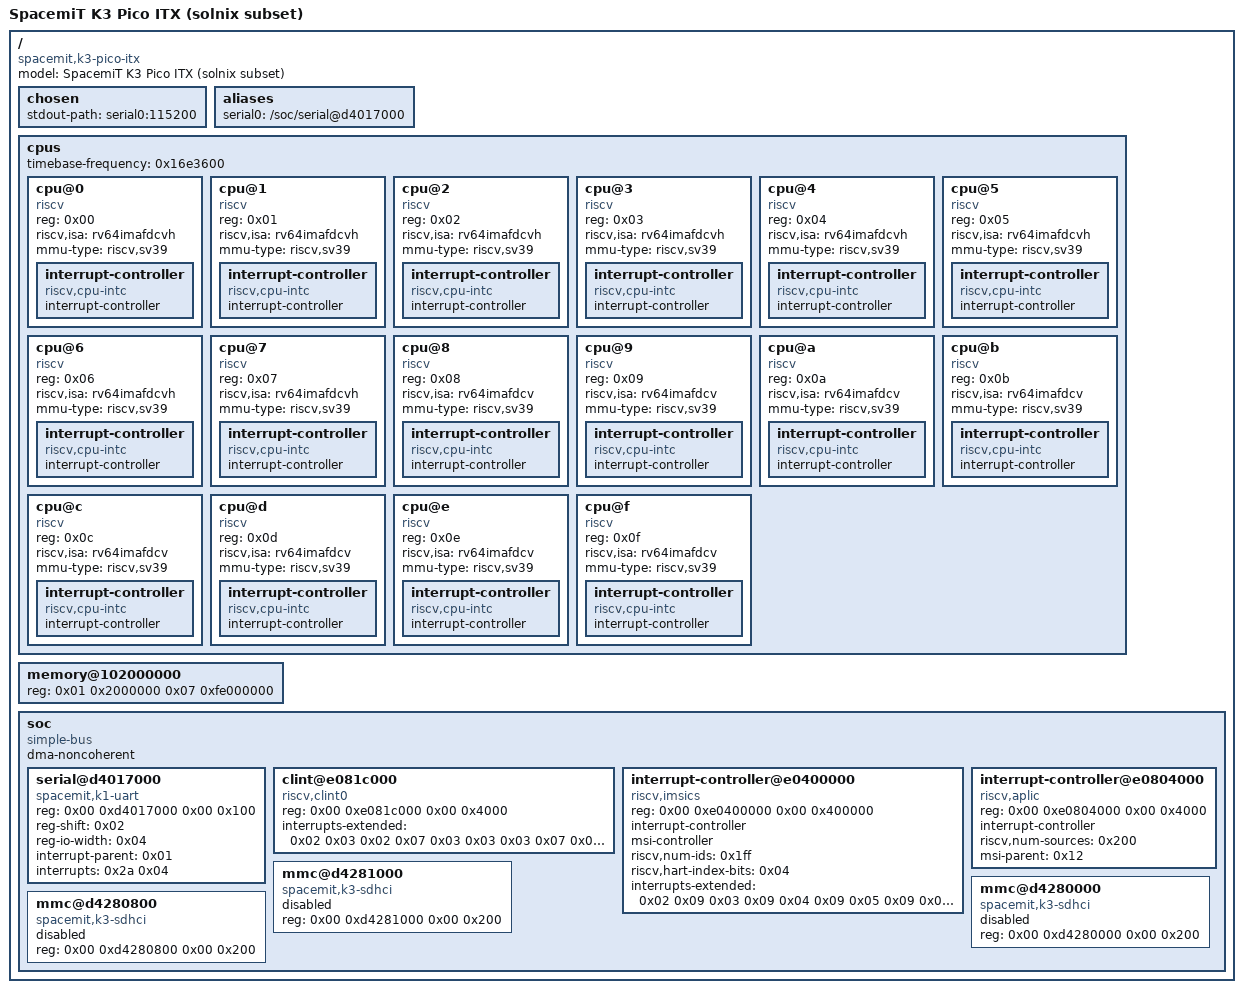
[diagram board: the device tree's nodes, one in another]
/dts-v1/;

/ {
	#address-cells = <0x02>;
	#size-cells = <0x02>;
	model = "SpacemiT K3 Pico ITX (solnix subset)";
	compatible = "spacemit,k3-pico-itx";

	chosen {
		stdout-path = "serial0:115200";
	};

	aliases {
		serial0 = "/soc/serial@d4017000";
	};

	cpus {
		#address-cells = <0x01>;
		#size-cells = <0x00>;
		timebase-frequency = <0x16e3600>;

		cpu@0 {
			device_type = "cpu";
			compatible = "riscv";
			reg = <0x00>;
			riscv,isa = "rv64imafdcvh";
			mmu-type = "riscv,sv39";
			status = "okay";

			interrupt-controller {
				compatible = "riscv,cpu-intc";
				#interrupt-cells = <0x01>;
				interrupt-controller;
				phandle = <0x02>;
			};
		};

		cpu@1 {
			device_type = "cpu";
			compatible = "riscv";
			reg = <0x01>;
			riscv,isa = "rv64imafdcvh";
			mmu-type = "riscv,sv39";
			status = "okay";

			interrupt-controller {
				compatible = "riscv,cpu-intc";
				#interrupt-cells = <0x01>;
				interrupt-controller;
				phandle = <0x03>;
			};
		};

		cpu@2 {
			device_type = "cpu";
			compatible = "riscv";
			reg = <0x02>;
			riscv,isa = "rv64imafdcvh";
			mmu-type = "riscv,sv39";
			status = "okay";

			interrupt-controller {
				compatible = "riscv,cpu-intc";
				#interrupt-cells = <0x01>;
				interrupt-controller;
				phandle = <0x04>;
			};
		};

		cpu@3 {
			device_type = "cpu";
			compatible = "riscv";
			reg = <0x03>;
			riscv,isa = "rv64imafdcvh";
			mmu-type = "riscv,sv39";
			status = "okay";

			interrupt-controller {
				compatible = "riscv,cpu-intc";
				#interrupt-cells = <0x01>;
				interrupt-controller;
				phandle = <0x05>;
			};
		};

		cpu@4 {
			device_type = "cpu";
			compatible = "riscv";
			reg = <0x04>;
			riscv,isa = "rv64imafdcvh";
			mmu-type = "riscv,sv39";
			status = "okay";

			interrupt-controller {
				compatible = "riscv,cpu-intc";
				#interrupt-cells = <0x01>;
				interrupt-controller;
				phandle = <0x06>;
			};
		};

		cpu@5 {
			device_type = "cpu";
			compatible = "riscv";
			reg = <0x05>;
			riscv,isa = "rv64imafdcvh";
			mmu-type = "riscv,sv39";
			status = "okay";

			interrupt-controller {
				compatible = "riscv,cpu-intc";
				#interrupt-cells = <0x01>;
				interrupt-controller;
				phandle = <0x07>;
			};
		};

		cpu@6 {
			device_type = "cpu";
			compatible = "riscv";
			reg = <0x06>;
			riscv,isa = "rv64imafdcvh";
			mmu-type = "riscv,sv39";
			status = "okay";

			interrupt-controller {
				compatible = "riscv,cpu-intc";
				#interrupt-cells = <0x01>;
				interrupt-controller;
				phandle = <0x08>;
			};
		};

		cpu@7 {
			device_type = "cpu";
			compatible = "riscv";
			reg = <0x07>;
			riscv,isa = "rv64imafdcvh";
			mmu-type = "riscv,sv39";
			status = "okay";

			interrupt-controller {
				compatible = "riscv,cpu-intc";
				#interrupt-cells = <0x01>;
				interrupt-controller;
				phandle = <0x09>;
			};
		};

		cpu@8 {
			device_type = "cpu";
			compatible = "riscv";
			reg = <0x08>;
			riscv,isa = "rv64imafdcv";
			mmu-type = "riscv,sv39";
			status = "okay";

			interrupt-controller {
				compatible = "riscv,cpu-intc";
				#interrupt-cells = <0x01>;
				interrupt-controller;
				phandle = <0x0a>;
			};
		};

		cpu@9 {
			device_type = "cpu";
			compatible = "riscv";
			reg = <0x09>;
			riscv,isa = "rv64imafdcv";
			mmu-type = "riscv,sv39";
			status = "okay";

			interrupt-controller {
				compatible = "riscv,cpu-intc";
				#interrupt-cells = <0x01>;
				interrupt-controller;
				phandle = <0x0b>;
			};
		};

		cpu@a {
			device_type = "cpu";
			compatible = "riscv";
			reg = <0x0a>;
			riscv,isa = "rv64imafdcv";
			mmu-type = "riscv,sv39";
			status = "okay";

			interrupt-controller {
				compatible = "riscv,cpu-intc";
				#interrupt-cells = <0x01>;
				interrupt-controller;
				phandle = <0x0c>;
			};
		};

		cpu@b {
			device_type = "cpu";
			compatible = "riscv";
			reg = <0x0b>;
			riscv,isa = "rv64imafdcv";
			mmu-type = "riscv,sv39";
			status = "okay";

			interrupt-controller {
				compatible = "riscv,cpu-intc";
				#interrupt-cells = <0x01>;
				interrupt-controller;
				phandle = <0x0d>;
			};
		};

		cpu@c {
			device_type = "cpu";
			compatible = "riscv";
			reg = <0x0c>;
			riscv,isa = "rv64imafdcv";
			mmu-type = "riscv,sv39";
			status = "okay";

			interrupt-controller {
				compatible = "riscv,cpu-intc";
				#interrupt-cells = <0x01>;
				interrupt-controller;
				phandle = <0x0e>;
			};
		};

		cpu@d {
			device_type = "cpu";
			compatible = "riscv";
			reg = <0x0d>;
			riscv,isa = "rv64imafdcv";
			mmu-type = "riscv,sv39";
			status = "okay";

			interrupt-controller {
				compatible = "riscv,cpu-intc";
				#interrupt-cells = <0x01>;
				interrupt-controller;
				phandle = <0x0f>;
			};
		};

		cpu@e {
			device_type = "cpu";
			compatible = "riscv";
			reg = <0x0e>;
			riscv,isa = "rv64imafdcv";
			mmu-type = "riscv,sv39";
			status = "okay";

			interrupt-controller {
				compatible = "riscv,cpu-intc";
				#interrupt-cells = <0x01>;
				interrupt-controller;
				phandle = <0x10>;
			};
		};

		cpu@f {
			device_type = "cpu";
			compatible = "riscv";
			reg = <0x0f>;
			riscv,isa = "rv64imafdcv";
			mmu-type = "riscv,sv39";
			status = "okay";

			interrupt-controller {
				compatible = "riscv,cpu-intc";
				#interrupt-cells = <0x01>;
				interrupt-controller;
				phandle = <0x11>;
			};
		};
	};

	memory@102000000 {
		device_type = "memory";
		reg = <0x01 0x2000000 0x07 0xfe000000>;
	};

	soc {
		compatible = "simple-bus";
		#address-cells = <0x02>;
		#size-cells = <0x02>;
		ranges;
		dma-noncoherent;

		serial@d4017000 {
			compatible = "spacemit,k1-uart", "intel,xscale-uart";
			reg = <0x00 0xd4017000 0x00 0x100>;
			reg-shift = <0x02>;
			reg-io-width = <0x04>;
			interrupt-parent = <0x01>;
			interrupts = <0x2a 0x04>;
			status = "okay";
		};

		clint@e081c000 {
			compatible = "riscv,clint0";
			reg = <0x00 0xe081c000 0x00 0x4000>;
			interrupts-extended = <0x02 0x03 0x02 0x07 0x03 0x03 0x03 0x07 0x04 0x03 0x04 0x07 0x05 0x03 0x05 0x07 0x06 0x03 0x06 0x07 0x07 0x03 0x07 0x07 0x08 0x03 0x08 0x07 0x09 0x03 0x09 0x07 0x0a 0x03 0x0a 0x07 0x0b 0x03 0x0b 0x07 0x0c 0x03 0x0c 0x07 0x0d 0x03 0x0d 0x07 0x0e 0x03 0x0e 0x07 0x0f 0x03 0x0f 0x07 0x10 0x03 0x10 0x07 0x11 0x03 0x11 0x07>;
		};

		interrupt-controller@e0400000 {
			compatible = "riscv,imsics";
			reg = <0x00 0xe0400000 0x00 0x400000>;
			interrupt-controller;
			msi-controller;
			#interrupt-cells = <0x00>;
			#msi-cells = <0x00>;
			riscv,num-ids = <0x1ff>;
			riscv,hart-index-bits = <0x04>;
			interrupts-extended = <0x02 0x09 0x03 0x09 0x04 0x09 0x05 0x09 0x06 0x09 0x07 0x09 0x08 0x09 0x09 0x09 0x0a 0x09 0x0b 0x09 0x0c 0x09 0x0d 0x09 0x0e 0x09 0x0f 0x09 0x10 0x09 0x11 0x09>;
			status = "okay";
			phandle = <0x12>;
		};

		interrupt-controller@e0804000 {
			compatible = "riscv,aplic";
			reg = <0x00 0xe0804000 0x00 0x4000>;
			interrupt-controller;
			#interrupt-cells = <0x02>;
			riscv,num-sources = <0x200>;
			msi-parent = <0x12>;
			status = "okay";
			phandle = <0x01>;
		};

		mmc@d4281000 {
			compatible = "spacemit,k3-sdhci";
			reg = <0x00 0xd4281000 0x00 0x200>;
			status = "disabled";
		};

		mmc@d4280000 {
			compatible = "spacemit,k3-sdhci";
			reg = <0x00 0xd4280000 0x00 0x200>;
			status = "disabled";
		};

		mmc@d4280800 {
			compatible = "spacemit,k3-sdhci";
			reg = <0x00 0xd4280800 0x00 0x200>;
			status = "disabled";
		};
	};
};
